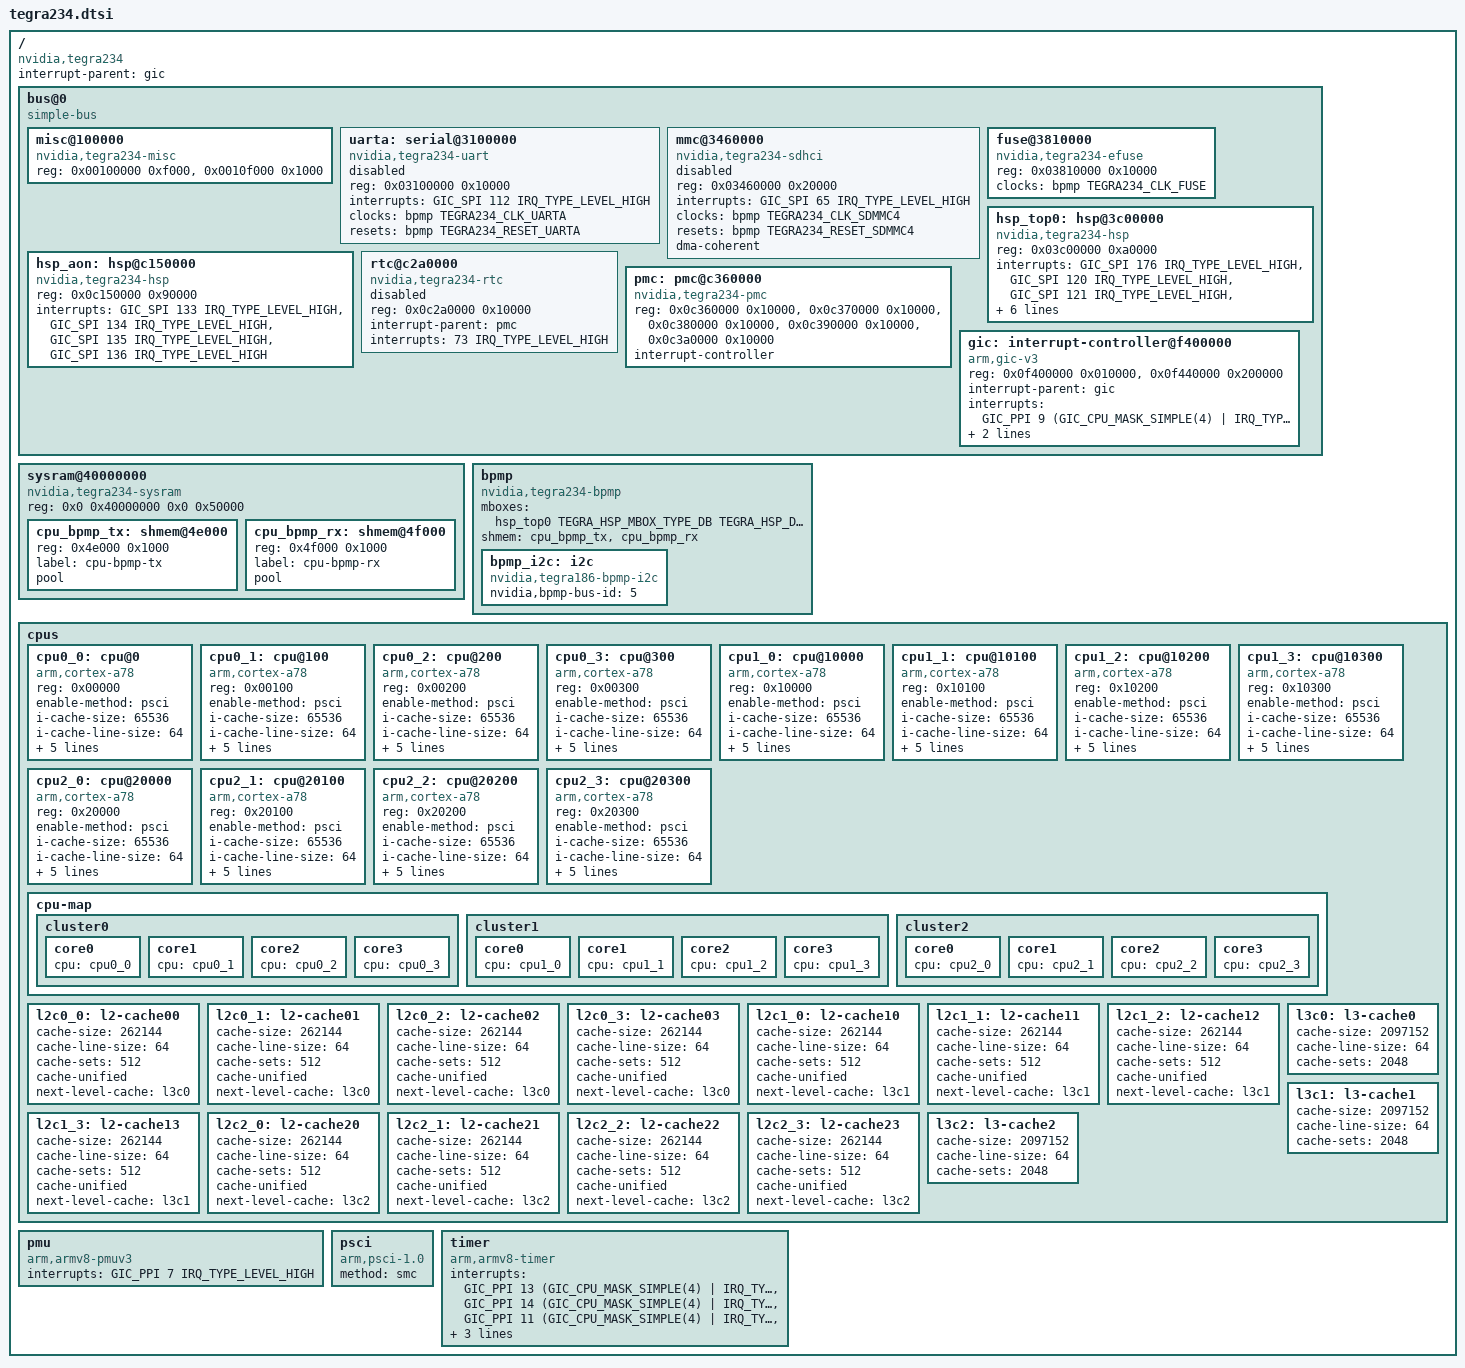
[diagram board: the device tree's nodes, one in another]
// SPDX-License-Identifier: GPL-2.0

#include <dt-bindings/clock/tegra234-clock.h>
#include <dt-bindings/interrupt-controller/arm-gic.h>
#include <dt-bindings/mailbox/tegra186-hsp.h>
#include <dt-bindings/reset/tegra234-reset.h>

/ {
	compatible = "nvidia,tegra234";
	interrupt-parent = <&gic>;
	#address-cells = <2>;
	#size-cells = <2>;

	bus@0 {
		compatible = "simple-bus";
		#address-cells = <1>;
		#size-cells = <1>;

		ranges = <0x0 0x0 0x0 0x40000000>;

		misc@100000 {
			compatible = "nvidia,tegra234-misc";
			reg = <0x00100000 0xf000>,
			      <0x0010f000 0x1000>;
			status = "okay";
		};

		uarta: serial@3100000 {
			compatible = "nvidia,tegra234-uart", "nvidia,tegra20-uart";
			reg = <0x03100000 0x10000>;
			interrupts = <GIC_SPI 112 IRQ_TYPE_LEVEL_HIGH>;
			clocks = <&bpmp TEGRA234_CLK_UARTA>;
			clock-names = "serial";
			resets = <&bpmp TEGRA234_RESET_UARTA>;
			reset-names = "serial";
			status = "disabled";
		};

		mmc@3460000 {
			compatible = "nvidia,tegra234-sdhci", "nvidia,tegra186-sdhci";
			reg = <0x03460000 0x20000>;
			interrupts = <GIC_SPI 65 IRQ_TYPE_LEVEL_HIGH>;
			clocks = <&bpmp TEGRA234_CLK_SDMMC4>;
			clock-names = "sdhci";
			resets = <&bpmp TEGRA234_RESET_SDMMC4>;
			reset-names = "sdhci";
			dma-coherent;
			status = "disabled";
		};

		fuse@3810000 {
			compatible = "nvidia,tegra234-efuse";
			reg = <0x03810000 0x10000>;
			clocks = <&bpmp TEGRA234_CLK_FUSE>;
			clock-names = "fuse";
		};

		hsp_top0: hsp@3c00000 {
			compatible = "nvidia,tegra234-hsp", "nvidia,tegra194-hsp";
			reg = <0x03c00000 0xa0000>;
			interrupts = <GIC_SPI 176 IRQ_TYPE_LEVEL_HIGH>,
				     <GIC_SPI 120 IRQ_TYPE_LEVEL_HIGH>,
				     <GIC_SPI 121 IRQ_TYPE_LEVEL_HIGH>,
				     <GIC_SPI 122 IRQ_TYPE_LEVEL_HIGH>,
				     <GIC_SPI 123 IRQ_TYPE_LEVEL_HIGH>,
				     <GIC_SPI 124 IRQ_TYPE_LEVEL_HIGH>,
				     <GIC_SPI 125 IRQ_TYPE_LEVEL_HIGH>,
				     <GIC_SPI 126 IRQ_TYPE_LEVEL_HIGH>,
				     <GIC_SPI 127 IRQ_TYPE_LEVEL_HIGH>;
			interrupt-names = "doorbell", "shared0", "shared1", "shared2",
					  "shared3", "shared4", "shared5", "shared6",
					  "shared7";
			#mbox-cells = <2>;
		};

		hsp_aon: hsp@c150000 {
			compatible = "nvidia,tegra234-hsp", "nvidia,tegra194-hsp";
			reg = <0x0c150000 0x90000>;
			interrupts = <GIC_SPI 133 IRQ_TYPE_LEVEL_HIGH>,
				     <GIC_SPI 134 IRQ_TYPE_LEVEL_HIGH>,
				     <GIC_SPI 135 IRQ_TYPE_LEVEL_HIGH>,
				     <GIC_SPI 136 IRQ_TYPE_LEVEL_HIGH>;
			/*
			 * Shared interrupt 0 is routed only to AON/SPE, so
			 * we only have 4 shared interrupts for the CCPLEX.
			 */
			interrupt-names = "shared1", "shared2", "shared3", "shared4";
			#mbox-cells = <2>;
		};

		rtc@c2a0000 {
			compatible = "nvidia,tegra234-rtc", "nvidia,tegra20-rtc";
			reg = <0x0c2a0000 0x10000>;
			interrupt-parent = <&pmc>;
			interrupts = <73 IRQ_TYPE_LEVEL_HIGH>;
			status = "disabled";
		};

		pmc: pmc@c360000 {
			compatible = "nvidia,tegra234-pmc";
			reg = <0x0c360000 0x10000>,
			      <0x0c370000 0x10000>,
			      <0x0c380000 0x10000>,
			      <0x0c390000 0x10000>,
			      <0x0c3a0000 0x10000>;
			reg-names = "pmc", "wake", "aotag", "scratch", "misc";

			#interrupt-cells = <2>;
			interrupt-controller;
		};

		gic: interrupt-controller@f400000 {
			compatible = "arm,gic-v3";
			reg = <0x0f400000 0x010000>, /* GICD */
			      <0x0f440000 0x200000>; /* GICR */
			interrupt-parent = <&gic>;
			interrupts = <GIC_PPI 9 (GIC_CPU_MASK_SIMPLE(4) | IRQ_TYPE_LEVEL_HIGH)>;

			#redistributor-regions = <1>;
			#interrupt-cells = <3>;
			interrupt-controller;
		};
	};

	sysram@40000000 {
		compatible = "nvidia,tegra234-sysram", "mmio-sram";
		reg = <0x0 0x40000000 0x0 0x50000>;
		#address-cells = <1>;
		#size-cells = <1>;
		ranges = <0x0 0x0 0x40000000 0x50000>;

		cpu_bpmp_tx: shmem@4e000 {
			reg = <0x4e000 0x1000>;
			label = "cpu-bpmp-tx";
			pool;
		};

		cpu_bpmp_rx: shmem@4f000 {
			reg = <0x4f000 0x1000>;
			label = "cpu-bpmp-rx";
			pool;
		};
	};

	bpmp: bpmp {
		compatible = "nvidia,tegra234-bpmp", "nvidia,tegra186-bpmp";
		mboxes = <&hsp_top0 TEGRA_HSP_MBOX_TYPE_DB
				    TEGRA_HSP_DB_MASTER_BPMP>;
		shmem = <&cpu_bpmp_tx &cpu_bpmp_rx>;
		#clock-cells = <1>;
		#reset-cells = <1>;
		#power-domain-cells = <1>;

		bpmp_i2c: i2c {
			compatible = "nvidia,tegra186-bpmp-i2c";
			nvidia,bpmp-bus-id = <5>;
			#address-cells = <1>;
			#size-cells = <0>;
		};
	};

	cpus {
		#address-cells = <1>;
		#size-cells = <0>;

		cpu0_0: cpu@0 {
			compatible = "arm,cortex-a78";
			device_type = "cpu";
			reg = <0x00000>;

			enable-method = "psci";

			i-cache-size = <65536>;
			i-cache-line-size = <64>;
			i-cache-sets = <256>;
			d-cache-size = <65536>;
			d-cache-line-size = <64>;
			d-cache-sets = <256>;
			next-level-cache = <&l2c0_0>;
		};

		cpu0_1: cpu@100 {
			compatible = "arm,cortex-a78";
			device_type = "cpu";
			reg = <0x00100>;

			enable-method = "psci";

			i-cache-size = <65536>;
			i-cache-line-size = <64>;
			i-cache-sets = <256>;
			d-cache-size = <65536>;
			d-cache-line-size = <64>;
			d-cache-sets = <256>;
			next-level-cache = <&l2c0_1>;
		};

		cpu0_2: cpu@200 {
			compatible = "arm,cortex-a78";
			device_type = "cpu";
			reg = <0x00200>;

			enable-method = "psci";

			i-cache-size = <65536>;
			i-cache-line-size = <64>;
			i-cache-sets = <256>;
			d-cache-size = <65536>;
			d-cache-line-size = <64>;
			d-cache-sets = <256>;
			next-level-cache = <&l2c0_2>;
		};

		cpu0_3: cpu@300 {
			compatible = "arm,cortex-a78";
			device_type = "cpu";
			reg = <0x00300>;

			enable-method = "psci";

			i-cache-size = <65536>;
			i-cache-line-size = <64>;
			i-cache-sets = <256>;
			d-cache-size = <65536>;
			d-cache-line-size = <64>;
			d-cache-sets = <256>;
			next-level-cache = <&l2c0_3>;
		};

		cpu1_0: cpu@10000 {
			compatible = "arm,cortex-a78";
			device_type = "cpu";
			reg = <0x10000>;

			enable-method = "psci";

			i-cache-size = <65536>;
			i-cache-line-size = <64>;
			i-cache-sets = <256>;
			d-cache-size = <65536>;
			d-cache-line-size = <64>;
			d-cache-sets = <256>;
			next-level-cache = <&l2c1_0>;
		};

		cpu1_1: cpu@10100 {
			compatible = "arm,cortex-a78";
			device_type = "cpu";
			reg = <0x10100>;

			enable-method = "psci";

			i-cache-size = <65536>;
			i-cache-line-size = <64>;
			i-cache-sets = <256>;
			d-cache-size = <65536>;
			d-cache-line-size = <64>;
			d-cache-sets = <256>;
			next-level-cache = <&l2c1_1>;
		};

		cpu1_2: cpu@10200 {
			compatible = "arm,cortex-a78";
			device_type = "cpu";
			reg = <0x10200>;

			enable-method = "psci";

			i-cache-size = <65536>;
			i-cache-line-size = <64>;
			i-cache-sets = <256>;
			d-cache-size = <65536>;
			d-cache-line-size = <64>;
			d-cache-sets = <256>;
			next-level-cache = <&l2c1_2>;
		};

		cpu1_3: cpu@10300 {
			compatible = "arm,cortex-a78";
			device_type = "cpu";
			reg = <0x10300>;

			enable-method = "psci";

			i-cache-size = <65536>;
			i-cache-line-size = <64>;
			i-cache-sets = <256>;
			d-cache-size = <65536>;
			d-cache-line-size = <64>;
			d-cache-sets = <256>;
			next-level-cache = <&l2c1_3>;
		};

		cpu2_0: cpu@20000 {
			compatible = "arm,cortex-a78";
			device_type = "cpu";
			reg = <0x20000>;

			enable-method = "psci";

			i-cache-size = <65536>;
			i-cache-line-size = <64>;
			i-cache-sets = <256>;
			d-cache-size = <65536>;
			d-cache-line-size = <64>;
			d-cache-sets = <256>;
			next-level-cache = <&l2c2_0>;
		};

		cpu2_1: cpu@20100 {
			compatible = "arm,cortex-a78";
			device_type = "cpu";
			reg = <0x20100>;

			enable-method = "psci";

			i-cache-size = <65536>;
			i-cache-line-size = <64>;
			i-cache-sets = <256>;
			d-cache-size = <65536>;
			d-cache-line-size = <64>;
			d-cache-sets = <256>;
			next-level-cache = <&l2c2_1>;
		};

		cpu2_2: cpu@20200 {
			compatible = "arm,cortex-a78";
			device_type = "cpu";
			reg = <0x20200>;

			enable-method = "psci";

			i-cache-size = <65536>;
			i-cache-line-size = <64>;
			i-cache-sets = <256>;
			d-cache-size = <65536>;
			d-cache-line-size = <64>;
			d-cache-sets = <256>;
			next-level-cache = <&l2c2_2>;
		};

		cpu2_3: cpu@20300 {
			compatible = "arm,cortex-a78";
			device_type = "cpu";
			reg = <0x20300>;

			enable-method = "psci";

			i-cache-size = <65536>;
			i-cache-line-size = <64>;
			i-cache-sets = <256>;
			d-cache-size = <65536>;
			d-cache-line-size = <64>;
			d-cache-sets = <256>;
			next-level-cache = <&l2c2_3>;
		};

		cpu-map {
			cluster0 {
				core0 {
					cpu = <&cpu0_0>;
				};

				core1 {
					cpu = <&cpu0_1>;
				};

				core2 {
					cpu = <&cpu0_2>;
				};

				core3 {
					cpu = <&cpu0_3>;
				};
			};

			cluster1 {
				core0 {
					cpu = <&cpu1_0>;
				};

				core1 {
					cpu = <&cpu1_1>;
				};

				core2 {
					cpu = <&cpu1_2>;
				};

				core3 {
					cpu = <&cpu1_3>;
				};
			};

			cluster2 {
				core0 {
					cpu = <&cpu2_0>;
				};

				core1 {
					cpu = <&cpu2_1>;
				};

				core2 {
					cpu = <&cpu2_2>;
				};

				core3 {
					cpu = <&cpu2_3>;
				};
			};
		};

		l2c0_0: l2-cache00 {
			cache-size = <262144>;
			cache-line-size = <64>;
			cache-sets = <512>;
			cache-unified;
			next-level-cache = <&l3c0>;
		};

		l2c0_1: l2-cache01 {
			cache-size = <262144>;
			cache-line-size = <64>;
			cache-sets = <512>;
			cache-unified;
			next-level-cache = <&l3c0>;
		};

		l2c0_2: l2-cache02 {
			cache-size = <262144>;
			cache-line-size = <64>;
			cache-sets = <512>;
			cache-unified;
			next-level-cache = <&l3c0>;
		};

		l2c0_3: l2-cache03 {
			cache-size = <262144>;
			cache-line-size = <64>;
			cache-sets = <512>;
			cache-unified;
			next-level-cache = <&l3c0>;
		};

		l2c1_0: l2-cache10 {
			cache-size = <262144>;
			cache-line-size = <64>;
			cache-sets = <512>;
			cache-unified;
			next-level-cache = <&l3c1>;
		};

		l2c1_1: l2-cache11 {
			cache-size = <262144>;
			cache-line-size = <64>;
			cache-sets = <512>;
			cache-unified;
			next-level-cache = <&l3c1>;
		};

		l2c1_2: l2-cache12 {
			cache-size = <262144>;
			cache-line-size = <64>;
			cache-sets = <512>;
			cache-unified;
			next-level-cache = <&l3c1>;
		};

		l2c1_3: l2-cache13 {
			cache-size = <262144>;
			cache-line-size = <64>;
			cache-sets = <512>;
			cache-unified;
			next-level-cache = <&l3c1>;
		};

		l2c2_0: l2-cache20 {
			cache-size = <262144>;
			cache-line-size = <64>;
			cache-sets = <512>;
			cache-unified;
			next-level-cache = <&l3c2>;
		};

		l2c2_1: l2-cache21 {
			cache-size = <262144>;
			cache-line-size = <64>;
			cache-sets = <512>;
			cache-unified;
			next-level-cache = <&l3c2>;
		};

		l2c2_2: l2-cache22 {
			cache-size = <262144>;
			cache-line-size = <64>;
			cache-sets = <512>;
			cache-unified;
			next-level-cache = <&l3c2>;
		};

		l2c2_3: l2-cache23 {
			cache-size = <262144>;
			cache-line-size = <64>;
			cache-sets = <512>;
			cache-unified;
			next-level-cache = <&l3c2>;
		};

		l3c0: l3-cache0 {
			cache-size = <2097152>;
			cache-line-size = <64>;
			cache-sets = <2048>;
		};

		l3c1: l3-cache1 {
			cache-size = <2097152>;
			cache-line-size = <64>;
			cache-sets = <2048>;
		};

		l3c2: l3-cache2 {
			cache-size = <2097152>;
			cache-line-size = <64>;
			cache-sets = <2048>;
		};
	};

	pmu {
		compatible = "arm,armv8-pmuv3";
		interrupts = <GIC_PPI 7 IRQ_TYPE_LEVEL_HIGH>;
		status = "okay";
	};

	psci {
		compatible = "arm,psci-1.0";
		status = "okay";
		method = "smc";
	};

	timer {
		compatible = "arm,armv8-timer";
		interrupts = <GIC_PPI 13 (GIC_CPU_MASK_SIMPLE(4) | IRQ_TYPE_LEVEL_LOW)>,
			     <GIC_PPI 14 (GIC_CPU_MASK_SIMPLE(4) | IRQ_TYPE_LEVEL_LOW)>,
			     <GIC_PPI 11 (GIC_CPU_MASK_SIMPLE(4) | IRQ_TYPE_LEVEL_LOW)>,
			     <GIC_PPI 10 (GIC_CPU_MASK_SIMPLE(4) | IRQ_TYPE_LEVEL_LOW)>;
		interrupt-parent = <&gic>;
		always-on;
	};
};
